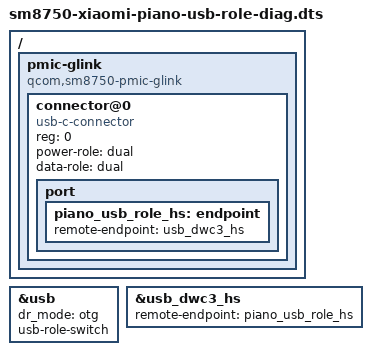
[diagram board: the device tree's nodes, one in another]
// SPDX-License-Identifier: BSD-3-Clause
/* Supervised USB2 role diagnostic. UCSI negotiation can remove the NCM link.
 * Requires a restricted module payload: no battmgr or altmode consumer.
 */

#include "sm8750-xiaomi-piano-adsp-diag.dts"

/ {
	pmic-glink {
		compatible = "qcom,sm8750-pmic-glink", "qcom,sm8550-pmic-glink",
			     "qcom,pmic-glink";
		#address-cells = <1>;
		#size-cells = <0>;

		connector@0 {
			compatible = "usb-c-connector";
			reg = <0>;
			power-role = "dual";
			data-role = "dual";

			port {
				piano_usb_role_hs: endpoint {
					remote-endpoint = <&usb_dwc3_hs>;
				};
			};
		};
	};
};

&usb {
	dr_mode = "otg";
	usb-role-switch;
};

&usb_dwc3_hs {
	remote-endpoint = <&piano_usb_role_hs>;
};
